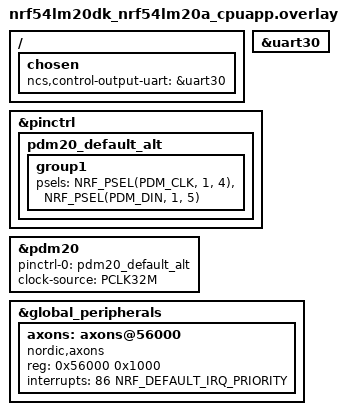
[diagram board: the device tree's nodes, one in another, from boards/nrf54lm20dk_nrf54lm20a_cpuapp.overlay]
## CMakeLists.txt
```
#
# Copyright (c) 2026 Nordic Semiconductor ASA
#
# SPDX-License-Identifier: LicenseRef-Nordic-5-Clause
#

cmake_minimum_required(VERSION 3.20.0)

find_package(Zephyr REQUIRED HINTS $ENV{ZEPHYR_BASE})
project(keyword_spotting)

target_sources(app PRIVATE
  src/main.c

  src/control_output.c
  src/dmic.c
  src/leds.c
  src/wakeword.c

  src/nrf_edgeai_generated/nrf_edgeai_user_model.c
)
```

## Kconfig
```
#
# Copyright (c) 2026 Nordic Semiconductor ASA
#
# SPDX-License-Identifier: LicenseRef-Nordic-5-Clause
#

menu "Keyword Spotting application"

config WW_PROBABILITY_THRESHOLD
	int "Wakeword probability threshold"
	range 0 100
	default 99
	help
	   Probability threshold for wakeword detection model. Value is expressed in percents.

config WW_HISTORY_SIZE
	int "Size of wakeword predictions history"
	range 1 32
	default 20
	help
	  Size of history of previous results from wakeword detection model. Each entry corresponds
	  to 30 milliseconds of past audio.

config WW_COUNT_THRESHOLD
	int "Threshold for wakeword detection from predictions history"
	range 1 WW_HISTORY_SIZE
	default 15
	help
	  Number of predictions above threshold in predictions history required to confirm wakeword
	  detection.

endmenu

source "Kconfig.zephyr"
```

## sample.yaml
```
sample:
  description: Keyword Spotting application
  name: keyword spotting

common:
  sysbuild: true
  build_only: true
  tags:
    - ci_build
    - sysbuild
    - ci_applications_keyword_spotting

tests:
  applications.keyword_spotting.zdebug:
    build_only: true
    platform_allow:
      - nrf54lm20dk/nrf54lm20a/cpuapp
    integration_platforms:
      - nrf54lm20dk/nrf54lm20a/cpuapp
```

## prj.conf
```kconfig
#
# Copyright (c) 2026 Nordic Semiconductor
#
# SPDX-License-Identifier: LicenseRef-Nordic-5-Clause
#

# nRF Edge AI
CONFIG_NRF_EDGEAI=y

# nRF Edge AI dependencies
CONFIG_NRF_AXON=y
CONFIG_NEWLIB_LIBC=y
CONFIG_FPU=y

# Size of interlayer buffer to fit model
CONFIG_NRF_AXON_INTERLAYER_BUFFER_SIZE=6048

# Size of psum buffer to fit model
CONFIG_NRF_AXON_PSUM_BUFFER_SIZE=0

# Enable sensor, button and LED libraries
CONFIG_GPIO=y
CONFIG_AUDIO=y
CONFIG_AUDIO_DMIC=y

# Enable logging and assert
CONFIG_LOG=y
CONFIG_CONSOLE=y
CONFIG_SERIAL=y
CONFIG_ASSERT=y

CONFIG_UART_ASYNC_API=y
```

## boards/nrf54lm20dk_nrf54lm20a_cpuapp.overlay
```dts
/*
 * Copyright (c) 2026 Nordic Semiconductor ASA
 *
 * SPDX-License-Identifier: LicenseRef-Nordic-5-Clause
 */

/ {
	chosen {
		ncs,control-output-uart = &uart30;
	};
};

&uart30 {
	status = "okay";
};

&pinctrl {
	pdm20_default_alt: pdm20_default_alt {
		group1 {
			psels = <NRF_PSEL(PDM_CLK, 1, 4)>,
				<NRF_PSEL(PDM_DIN, 1, 5)>;
		};
	};
};

dmic_dev: &pdm20 {
	status = "okay";
	pinctrl-0 = <&pdm20_default_alt>;
	pinctrl-names = "default";
	clock-source = "PCLK32M";
};

&global_peripherals {
	axons: axons@56000 {
		compatible = "nordic,axons";
		reg = <0x56000 0x1000>;
		interrupts = <86 NRF_DEFAULT_IRQ_PRIORITY>;
		status = "okay";
	};
};
```

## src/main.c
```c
/*
 * Copyright (c) 2026 Nordic Semiconductor ASA
 *
 * SPDX-License-Identifier: LicenseRef-Nordic-5-Clause
 */

#include "control_output.h"
#include "dmic.h"
#include "leds.h"
#include "wakeword.h"

#include <stddef.h>
#include <stdint.h>

#include <zephyr/audio/dmic.h>
#include <zephyr/device.h>
#include <zephyr/devicetree.h>
#include <zephyr/logging/log.h>

LOG_MODULE_REGISTER(main);

static const struct device *const dmic_dev = DEVICE_DT_GET(DT_NODELABEL(dmic_dev));

int main(void)
{
	int err;

	err = dmic_init();
	if (err) {
		return err;
	}

	err = leds_init();
	if (err) {
		return err;
	}

	err = control_output_init();
	if (err) {
		return err;
	}

	err = ww_init();
	if (err) {
		return err;
	}

	err = dmic_trigger(dmic_dev, DMIC_TRIGGER_START);
	if (err < 0) {
		LOG_ERR("Failed to start DMIC (err %d)", err);
		return err;
	}

	void *audio_buffer;
	uint32_t audio_buffer_size;
	bool ww_detected;

	print_control_output((struct control_message){CONTROL_MESSAGE_WAITING_WW});

	while (true) {
		const int32_t read_timeout = 100;

		err = dmic_read(dmic_dev, 0, &audio_buffer, &audio_buffer_size, read_timeout);
		if (err < 0) {
			LOG_ERR("Failed to read from DMIC (err %d)", err);
			return err;
		}

		err = ww_process(audio_buffer, audio_buffer_size / DMIC_SAMPLE_BYTES, &ww_detected);
		if (err == -EBUSY) {
			/* More data is needed. */
			continue;
		} else if (err < 0) {
			LOG_ERR("Wakeword detection failed (err %d)", err);
			return err;
		}

		if (ww_detected) {
			leds_blink_led0();
			print_control_output((struct control_message){CONTROL_MESSAGE_WW_DETECTED});
		}
	}

	return 0;
}
```

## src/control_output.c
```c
/*
 * Copyright (c) 2026 Nordic Semiconductor ASA
 *
 * SPDX-License-Identifier: LicenseRef-Nordic-5-Clause
 */

#include "control_output.h"

#include <stdalign.h>
#include <stddef.h>
#include <stdio.h>

#include <zephyr/device.h>
#include <zephyr/devicetree.h>
#include <zephyr/drivers/uart.h>
#include <zephyr/kernel.h>
#include <zephyr/logging/log.h>
#include <zephyr/sys/atomic.h>

LOG_MODULE_REGISTER(control_output);

struct k_work control_output_work;

K_MSGQ_DEFINE(control_msg_queue, sizeof(struct control_message), 10,
	      alignof(struct control_message));

static const char waiting_ww_msg[] = "Waiting for wakeword\r\n";
static const char detected_ww_msg[] = "Wakeword detected\r\n";

static const struct device *uart_dev = DEVICE_DT_GET(DT_CHOSEN(ncs_control_output_uart));
static atomic_t uart_busy;

static void uart_cb(const struct device *dev, struct uart_event *evt, void *user_data)
{
	int err;

	if (evt->type == UART_TX_DONE) {
		atomic_set(&uart_busy, false);

		if (k_msgq_num_used_get(&control_msg_queue) == 0) {
			return;
		}

		err = k_work_submit(&control_output_work);
		if (err < 0) {
			LOG_ERR("Failed to submit work (err %d)", err);
		}
	}
}

static void control_output_work_handler(struct k_work *work)
{
	int err;
	struct control_message message_item;

	const char *buffer = NULL;
	size_t buffer_len = 0;

	if (atomic_get(&uart_busy)) {
		return;
	}

	err = k_msgq_peek(&control_msg_queue, &message_item);
	if (err) {
		return;
	}

	atomic_set(&uart_busy, true);

	switch (message_item.type) {
	case CONTROL_MESSAGE_WAITING_WW:
		buffer_len = sizeof(waiting_ww_msg) - 1;
		buffer = waiting_ww_msg;
		break;
	case CONTROL_MESSAGE_WW_DETECTED:
		buffer_len = sizeof(detected_ww_msg) - 1;
		buffer = detected_ww_msg;
		break;
	default:
		atomic_set(&uart_busy, false);
		LOG_ERR("Unhandled case");
		return;
	}

	err = uart_tx(uart_dev, buffer, buffer_len, 0);
	if (err) {
		atomic_set(&uart_busy, false);
		LOG_ERR("Failed to transmit data (err %d)", err);
		return;
	}

	k_msgq_get(&control_msg_queue, &message_item, K_NO_WAIT);
}

int control_output_init(void)
{
	int err;

	if (!device_is_ready(uart_dev)) {
		LOG_ERR("Device is not ready");
		return -ENODEV;
	}

	err = uart_callback_set(uart_dev, uart_cb, NULL);
	if (err) {
		LOG_ERR("Failed to set UART callback (err %d)", err);
	}

	k_work_init(&control_output_work, control_output_work_handler);

	return err;
}

void print_control_output(const struct control_message message)
{
	int err;

	err = k_msgq_put(&control_msg_queue, &message, K_NO_WAIT);
	if (err) {
		LOG_ERR("Failed to put message in queue (err %d)", err);
		return;
	}

	err = k_work_submit(&control_output_work);
	if (err < 0) {
		LOG_ERR("Failed to submit work (err %d)", err);
	}
}
```

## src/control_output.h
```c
/*
 * Copyright (c) 2026 Nordic Semiconductor ASA
 *
 * SPDX-License-Identifier: LicenseRef-Nordic-5-Clause
 */

/**
 * @defgroup control_output Printing control output functions
 * @{
 * @ingroup keyword_spotting
 */

#ifndef __CONTROL_OUTPUT_H__
#define __CONTROL_OUTPUT_H__

#ifdef __cplusplus
extern "C" {
#endif /* __cplusplus */

/**
 * @brief Control message type.
 */
enum control_message_type {
	CONTROL_MESSAGE_WAITING_WW,
	CONTROL_MESSAGE_WW_DETECTED,
};

/**
 * @brief Control message.
 */
struct control_message {
	enum control_message_type type;
};

/**
 * @brief Initialize control output backend.
 *
 * @return Operation status, 0 for success.
 */
int control_output_init(void);

/**
 * @brief Initialize LEDs.
 *
 * @param message Control message to be printed.
 */
void print_control_output(const struct control_message message);

#ifdef __cplusplus
}
#endif /* __cplusplus */

#endif /* __CONTROL_OUTPUT_H__ */

/**
 * @}
 */
```

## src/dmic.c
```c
/*
 * Copyright (c) 2026 Nordic Semiconductor ASA
 *
 * SPDX-License-Identifier: LicenseRef-Nordic-5-Clause
 */

#include "dmic.h"

#include <stddef.h>

#include <zephyr/audio/dmic.h>
#include <zephyr/device.h>
#include <zephyr/devicetree.h>
#include <zephyr/kernel.h>
#include <zephyr/logging/log.h>

LOG_MODULE_REGISTER(dmic);

#define BLOCK_SIZE (DMIC_SAMPLE_BYTES * DMIC_PCM_RATE * SAMPLES_BLOCK_LENGTH_MS / 1000)

K_MEM_SLAB_DEFINE_STATIC(dmic_mem_slab, BLOCK_SIZE, 4, 4);

int dmic_init(void)
{
	int err;
	const struct device *const dmic_dev = DEVICE_DT_GET(DT_NODELABEL(dmic_dev));

	if (!device_is_ready(dmic_dev)) {
		LOG_ERR("Device is not ready");
		return -ENODEV;
	}

	struct pcm_stream_cfg stream = {
		.pcm_rate = DMIC_PCM_RATE,
		.pcm_width = DMIC_SAMPLE_BYTES * 8,
		.block_size = BLOCK_SIZE,
		.mem_slab = &dmic_mem_slab,
	};
	struct dmic_cfg cfg = {
		.io = {
			.min_pdm_clk_freq = 1000000,
			.max_pdm_clk_freq = 3250000,
			.min_pdm_clk_dc = 40,
			.max_pdm_clk_dc = 60,
		},
		.streams = &stream,
		.channel = {
			.req_chan_map_lo = dmic_build_channel_map(0, 0, PDM_CHAN_LEFT),
			.req_chan_map_hi = 0,
			.req_num_chan = 1,
			.req_num_streams = 1,
		},
	};

	err = dmic_configure(dmic_dev, &cfg);
	if (err < 0) {
		LOG_ERR("Failed to configure (err %d)", err);
		return err;
	}

	return 0;
}

void free_dmic_buffer(void *buffer)
{
	k_mem_slab_free(&dmic_mem_slab, buffer);
}
```

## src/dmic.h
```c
/*
 * Copyright (c) 2026 Nordic Semiconductor ASA
 *
 * SPDX-License-Identifier: LicenseRef-Nordic-5-Clause
 */

/**
 * @defgroup dmic DMIC control functions
 * @{
 * @ingroup keyword_spotting
 */

#ifndef __DMIC_H__
#define __DMIC_H__

#ifdef __cplusplus
extern "C" {
#endif /* __cplusplus */

#define DMIC_SAMPLE_BYTES	(2)
#define DMIC_PCM_RATE		(16000)
#define SAMPLES_BLOCK_LENGTH_MS (10)

/**
 * @brief Initialize DMIC.
 *
 * @return Operation status result, 0 for success.
 */
int dmic_init(void);

/**
 * @brief Free the audio buffer acquired with  dmic_read.
 *
 * @param buffer Audio buffer.
 */
void free_dmic_buffer(void *buffer);

#ifdef __cplusplus
}
#endif /* __cplusplus */

#endif /* __DMIC_H__ */

/**
 * @}
 */
```

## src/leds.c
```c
/*
 * Copyright (c) 2026 Nordic Semiconductor ASA
 *
 * SPDX-License-Identifier: LicenseRef-Nordic-5-Clause
 */

#include <zephyr/devicetree.h>
#include <zephyr/drivers/gpio.h>
#include <zephyr/kernel.h>
#include <zephyr/logging/log.h>

LOG_MODULE_REGISTER(leds);

static const struct gpio_dt_spec led0 = GPIO_DT_SPEC_GET(DT_ALIAS(led0), gpios);

static void led_timer_expiry(struct k_timer *timer);
static K_TIMER_DEFINE(led_timer, led_timer_expiry, NULL);

int leds_init(void)
{
	int err;

	if (!gpio_is_ready_dt(&led0)) {
		LOG_ERR("GPIO is not ready");
		return -ENODEV;
	}

	err = gpio_pin_configure_dt(&led0, GPIO_OUTPUT_ACTIVE);
	if (err) {
		LOG_ERR("Failed to configure GPIO pin (err %d)", err);
		return err;
	}

	return 0;
}

void leds_blink_led0(void)
{
	gpio_pin_set_dt(&led0, 1);
	k_timer_start(&led_timer, K_SECONDS(1), K_NO_WAIT);
}

static void led_timer_expiry(struct k_timer *timer)
{
	gpio_pin_set_dt(&led0, 0);
}
```

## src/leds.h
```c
/*
 * Copyright (c) 2026 Nordic Semiconductor ASA
 *
 * SPDX-License-Identifier: LicenseRef-Nordic-5-Clause
 */

/**
 * @defgroup leds LEDs control functions
 * @{
 * @ingroup keyword_spotting
 */

#ifndef __LEDS_H__
#define __LEDS_H__

#ifdef __cplusplus
extern "C" {
#endif /* __cplusplus */

/**
 * @brief Initialize LEDs.
 *
 * @return Operation status, 0 for success.
 */
int leds_init(void);

/**
 * @brief Blink with LED0.
 */
void leds_blink_led0(void);

#ifdef __cplusplus
}
#endif /* __cplusplus */

#endif /* __LEDS_H__ */

/**
 * @}
 */
```

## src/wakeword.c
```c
/*
 * Copyright (c) 2026 Nordic Semiconductor ASA
 *
 * SPDX-License-Identifier: LicenseRef-Nordic-5-Clause
 */

#include "dmic.h"
#include "wakeword.h"

#include "nrf_edgeai_generated/nrf_edgeai_user_model.h"

#include <stddef.h>
#include <stdint.h>

#include <zephyr/logging/log.h>

#include <nrf_edgeai/nrf_edgeai.h>

LOG_MODULE_REGISTER(ww);

#define WW_THRESHOLD	    (0.97f)
#define WW_HISTORY_SIZE	    (20)
#define WW_PREDICTION_COUNT (15)

static nrf_edgeai_t *ww_model;

int ww_init(void)
{
	ww_model = nrf_edgeai_user_model_wakeword();
	__ASSERT_NO_MSG(ww_model);

	nrf_edgeai_err_t err = nrf_edgeai_init(ww_model);

	if (err) {
		LOG_ERR("Model initialization failed (err %d)", err);
		return -ENOENT;
	}

	return 0;
}

static bool ww_postprocess(void)
{
	static uint32_t ww_count;
	static uint32_t ww_history;

	const uint16_t predicted_class = ww_model->decoded_output.classif.predicted_class;
	const float class_probability =
		ww_model->decoded_output.classif.probabilities.p_f32[predicted_class];
	const bool ww_detected = class_probability > CONFIG_WW_PROBABILITY_THRESHOLD;

	const bool oldest_entry = (bool)(ww_history & BIT(CONFIG_WW_HISTORY_SIZE - 1));

	ww_count = ww_count + ww_detected - oldest_entry;
	ww_history = (ww_history << 1) | ww_detected;

	LOG_DBG("postprocess: count: %2u, probability: %f", ww_count, (double)class_probability);

	if (ww_count >= CONFIG_WW_COUNT_THRESHOLD) {
		ww_count = 0;
		ww_history = 0;

		return true;
	}

	return false;
}

int ww_process(uint8_t *const audio_buffer, const uint16_t num_samples, bool *const ww_detected)
{
	__ASSERT_NO_MSG(audio_buffer);
	__ASSERT_NO_MSG(num_samples == nrf_edgeai_input_window_size(ww_model));
	__ASSERT_NO_MSG(ww_detected);

	nrf_edgeai_err_t err;

	err = nrf_edgeai_feed_inputs(ww_model, audio_buffer, num_samples);
	free_dmic_buffer(audio_buffer);

	if (err == NRF_EDGEAI_ERR_INPROGRESS) {
		/* Skip inference, not enough data. */
		return -EBUSY;
	} else if (err) {
		LOG_ERR("Failed to feed inputs (err %d)", err);
		return -EPERM;
	}

	err = nrf_edgeai_run_inference(ww_model);
	if (err == NRF_EDGEAI_ERR_INPROGRESS) {
		/* Skip output extraction, not enough data. */
		return -EBUSY;
	} else if (err) {
		LOG_ERR("Failed to run inference (err %d)", err);
		return -EPERM;
	}

	*ww_detected = ww_postprocess();

	return 0;
}
```

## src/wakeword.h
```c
/*
 * Copyright (c) 2026 Nordic Semiconductor ASA
 *
 * SPDX-License-Identifier: LicenseRef-Nordic-5-Clause
 */

/**
 * @defgroup keyword_spotting Keyword Spotting application
 */

/**
 * @defgroup wakeword Wakeword model functions
 * @{
 * @ingroup keyword_spotting
 */

#ifndef __WAKEWORD_H__
#define __WAKEWORD_H__

#include <stdbool.h>
#include <stdint.h>

#ifdef __cplusplus
extern "C" {
#endif /* __cplusplus */

/**
 * @brief Initialize Wakeword model.
 *
 * @return Operation status, 0 for success.
 */
int ww_init(void);

/**
 * @brief Process audio data by Wakeword model.
 *
 * @param audio_buffer Buffer of audio samples from dmic_read. Function takes ownership of pointer.
 * @param num_samples Number of audio samples.
 * @param[out] ww_detected Result of wakeword detection. Valid if operation completed successfully.

 * @retval 0 Operation successful.
 * @retval -EPERM Operation failed on nRF Edge AI Lib level.
 * @retval -EBUSY Model needs more data.
 */
int ww_process(uint8_t *const audio_buffer, const uint16_t num_samples, bool *const ww_detected);

#ifdef __cplusplus
}
#endif /* __cplusplus */

#endif /* __WAKEWORD_H__ */

/**
 * @}
 */
```
